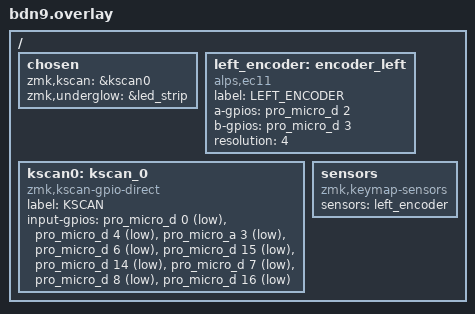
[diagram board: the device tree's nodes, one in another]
/{
    chosen {
        zmk,kscan = &kscan0;
        zmk,underglow = &led_strip;
    };
    
    left_encoder: encoder_left {
        compatible = "alps,ec11";
        label = "LEFT_ENCODER";
        a-gpios = <&pro_micro_d  2 (GPIO_ACTIVE_HIGH | GPIO_PULL_UP)>;
        b-gpios = <&pro_micro_d  3 (GPIO_ACTIVE_HIGH | GPIO_PULL_UP)>;
        resolution = <4>;
        status = "okay";
    };

    kscan0: kscan_0 {
        compatible = "zmk,kscan-gpio-direct";
        label = "KSCAN";

        input-gpios
            = <&pro_micro_d 0 (GPIO_ACTIVE_LOW | GPIO_PULL_UP)>
            , <&pro_micro_d 4 (GPIO_ACTIVE_LOW | GPIO_PULL_UP)>
            , <&pro_micro_a 3 (GPIO_ACTIVE_LOW | GPIO_PULL_UP)>
            , <&pro_micro_d 6 (GPIO_ACTIVE_LOW | GPIO_PULL_UP)>
            , <&pro_micro_d 15 (GPIO_ACTIVE_LOW | GPIO_PULL_UP)>
            , <&pro_micro_d 14 (GPIO_ACTIVE_LOW | GPIO_PULL_UP)>
            , <&pro_micro_d 7 (GPIO_ACTIVE_LOW | GPIO_PULL_UP)>
            , <&pro_micro_d 8 (GPIO_ACTIVE_LOW | GPIO_PULL_UP)>
            , <&pro_micro_d 16 (GPIO_ACTIVE_LOW | GPIO_PULL_UP)>
            ;
    };

    sensors {
        compatible = "zmk,keymap-sensors";
        sensors = <&left_encoder>;
    };
};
